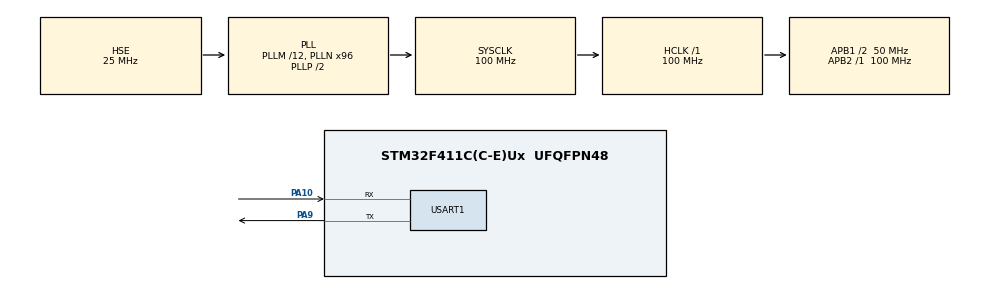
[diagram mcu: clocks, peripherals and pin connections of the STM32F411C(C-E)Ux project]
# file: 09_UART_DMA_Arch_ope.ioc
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Mcu.Family=STM32F4
Mcu.Name=STM32F411C(C-E)Ux
Mcu.Package=UFQFPN48
NVIC.PriorityGroup=NVIC_PRIORITYGROUP_4
NVIC.TIM1_UP_TIM10_IRQn=true\:15\:0\:false\:false\:true\:false\:true\:true
NVIC.TimeBase=TIM1_UP_TIM10_IRQn
NVIC.TimeBaseIP=TIM1
NVIC.USART1_IRQn=true\:5\:0\:true\:false\:true\:true\:true\:true
PA10.Mode=Asynchronous
PA10.Signal=USART1_RX
PA13.Mode=Serial_Wire
PA13.Signal=SYS_JTMS-SWDIO
PA14.Mode=Serial_Wire
PA14.Signal=SYS_JTCK-SWCLK
PA9.Mode=Asynchronous
PA9.Signal=USART1_TX
PC14-OSC32_IN.Mode=LSE-External-Oscillator
PC14-OSC32_IN.Signal=RCC_OSC32_IN
PC15-OSC32_OUT.Mode=LSE-External-Oscillator
PC15-OSC32_OUT.Signal=RCC_OSC32_OUT
PH0\ -\ OSC_IN.Mode=HSE-External-Oscillator
PH0\ -\ OSC_IN.Signal=RCC_OSC_IN
PH1\ -\ OSC_OUT.Mode=HSE-External-Oscillator
PH1\ -\ OSC_OUT.Signal=RCC_OSC_OUT
ProjectManager.HeapSize=0x200
ProjectManager.StackSize=0x400
ProjectManager.TargetToolchain=MDK-ARM V5.32
RCC.48MHZClocksFreq_Value=50000000
RCC.AHBFreq_Value=100000000
RCC.APB1CLKDivider=RCC_HCLK_DIV2
RCC.APB1Freq_Value=50000000
RCC.APB1TimFreq_Value=100000000
RCC.APB2Freq_Value=100000000
RCC.APB2TimFreq_Value=100000000
RCC.CortexFreq_Value=100000000
RCC.HCLKFreq_Value=100000000
RCC.HSE_VALUE=25000000
RCC.HSI_VALUE=16000000
RCC.PLLM=12
RCC.PLLN=96
RCC.PLLSourceVirtual=RCC_PLLSOURCE_HSE
RCC.SYSCLKFreq_VALUE=100000000
RCC.SYSCLKSource=RCC_SYSCLKSOURCE_PLLCLK
RCC.VCOOutputFreq_Value=200000000
USART1.VirtualMode=VM_ASYNC
VP_SYS_VS_tim1.Mode=TIM1
board=custom

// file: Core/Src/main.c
/* USER CODE BEGIN Header */
/**
  ******************************************************************************
  * @file           : main.c
  * @brief          : Main program body
  ******************************************************************************
  * @attention
  *
  * Copyright (c) 2025 STMicroelectronics.
  * All rights reserved.
  *
  * This software is licensed under terms that can be found in the LICENSE file
  * in the root directory of this software component.
  * If no LICENSE file comes with this software, it is provided AS-IS.
  *
  ******************************************************************************
  */
/* USER CODE END Header */
#include "main.h"
#include "usart.h"
#include "gpio.h"

/* USER CODE BEGIN Includes */
#include "stdio.h"

#include "SEGGER_RTT.h"
#include "elog.h"
/* USER CODE END Includes */

void SystemClock_Config(void);
/* USER CODE BEGIN PFP */
static void test_elog(void);
/* USER CODE END PFP */

/* USER CODE BEGIN 0 */
#ifdef __GNUC__
/* With GCC, small printf (option LD Linker->Libraries->Small printf
   set to 'Yes') calls __io_putchar() */
#define PUTCHAR_PROTOTYPE int __io_putchar(int ch)
#else
#define PUTCHAR_PROTOTYPE int fputc(int ch, FILE *f)
#endif /* __GNUC__ */

/**
  * @brief  Retargets the C library printf function to the USART.
  * @param  None
  * @retval None
  */
PUTCHAR_PROTOTYPE
{
  /* Place your implementation of fputc here */
  /* e.g. write a character to the USART3 and Loop until the end of transmission */
  //HAL_UART_Transmit(&huart1, (uint8_t *)&ch, 1, 0xFFFF);
	SEGGER_RTT_PutChar(0, ch);

  return ch;
}
/* USER CODE END 0 */

int main(void)
{

  /* MCU Configuration--------------------------------------------------------*/

  /* Reset of all peripherals, Initializes the Flash interface and the Systick. */
  HAL_Init();

  /* Configure the system clock */
  SystemClock_Config();

  /* Initialize all configured peripherals */
  MX_GPIO_Init();
  MX_USART1_UART_Init();
  /* USER CODE BEGIN 2 */
    /* initialize EasyLogger */
    elog_init();
    /* set EasyLogger log format */
    elog_set_fmt(ELOG_LVL_ASSERT, 0);
    elog_set_fmt(ELOG_LVL_ERROR, ELOG_FMT_LVL | ELOG_FMT_TAG | ELOG_FMT_TIME);
    elog_set_fmt(ELOG_LVL_WARN, ELOG_FMT_LVL | ELOG_FMT_TAG | ELOG_FMT_TIME);
    elog_set_fmt(ELOG_LVL_INFO, ELOG_FMT_LVL | ELOG_FMT_TAG | ELOG_FMT_TIME);
    elog_set_fmt(ELOG_LVL_DEBUG, ELOG_FMT_ALL & ~(ELOG_FMT_FUNC | ELOG_FMT_T_INFO | ELOG_FMT_P_INFO));
    elog_set_fmt(ELOG_LVL_VERBOSE, ELOG_FMT_ALL & ~(ELOG_FMT_FUNC | ELOG_FMT_T_INFO | ELOG_FMT_P_INFO));
    /* start EasyLogger */
    elog_start();
  /* USER CODE END 2 */

  /* Infinite loop */
  while (1)
  {

    /* USER CODE BEGIN 3 */
		/* ------ SEGGER-RTT-OUTPUT-TEST ------ */
		//SEGGER_RTT_printf(0,RTT_CTRL_BG_BRIGHT_BLUE"Helloworld\r\n");
		//printf("Helloworld %f\r\n",3.14159);

		/* ------  Easylog -OUTPUT-TEST  ------ */
		test_elog();

		HAL_Delay(2000);
  }
  /* USER CODE END 3 */
}

void SystemClock_Config(void)
{
  RCC_OscInitTypeDef RCC_OscInitStruct = {0};
  RCC_ClkInitTypeDef RCC_ClkInitStruct = {0};

  /** Configure the main internal regulator output voltage
  */
  __HAL_RCC_PWR_CLK_ENABLE();
  __HAL_PWR_VOLTAGESCALING_CONFIG(PWR_REGULATOR_VOLTAGE_SCALE1);

  /** Initializes the RCC Oscillators according to the specified parameters
  * in the RCC_OscInitTypeDef structure.
  */
  RCC_OscInitStruct.OscillatorType = RCC_OSCILLATORTYPE_HSE;
  RCC_OscInitStruct.HSEState = RCC_HSE_ON;
  RCC_OscInitStruct.PLL.PLLState = RCC_PLL_ON;
  RCC_OscInitStruct.PLL.PLLSource = RCC_PLLSOURCE_HSE;
  RCC_OscInitStruct.PLL.PLLM = 12;
  RCC_OscInitStruct.PLL.PLLN = 96;
  RCC_OscInitStruct.PLL.PLLP = RCC_PLLP_DIV2;
  RCC_OscInitStruct.PLL.PLLQ = 4;
  if (HAL_RCC_OscConfig(&RCC_OscInitStruct) != HAL_OK)
  {
    Error_Handler();
  }

  /** Initializes the CPU, AHB and APB buses clocks
  */
  RCC_ClkInitStruct.ClockType = RCC_CLOCKTYPE_HCLK|RCC_CLOCKTYPE_SYSCLK
                              |RCC_CLOCKTYPE_PCLK1|RCC_CLOCKTYPE_PCLK2;
  RCC_ClkInitStruct.SYSCLKSource = RCC_SYSCLKSOURCE_PLLCLK;
  RCC_ClkInitStruct.AHBCLKDivider = RCC_SYSCLK_DIV1;
  RCC_ClkInitStruct.APB1CLKDivider = RCC_HCLK_DIV2;
  RCC_ClkInitStruct.APB2CLKDivider = RCC_HCLK_DIV1;

  if (HAL_RCC_ClockConfig(&RCC_ClkInitStruct, FLASH_LATENCY_3) != HAL_OK)
  {
    Error_Handler();
  }
}

/* USER CODE BEGIN 4 */
static void test_elog(void) {
    /* test log output for all level */
	log_a("tick:%ld,Helloworld",HAL_GetTick());
//    log_e("Hello EasyLogger!");
//    log_w("Hello EasyLogger!");
//    log_i("Hello EasyLogger!");
//    log_d("Hello EasyLogger!");
//    log_v("Hello EasyLogger!");
//    elog_raw("Hello EasyLogger!");
}

/* USER CODE END 4 */

void HAL_TIM_PeriodElapsedCallback(TIM_HandleTypeDef *htim)
{
  if (htim->Instance == TIM1) {
    HAL_IncTick();
  }
}

void Error_Handler(void)
{
  __disable_irq();
  while (1)
  {
  }
}
